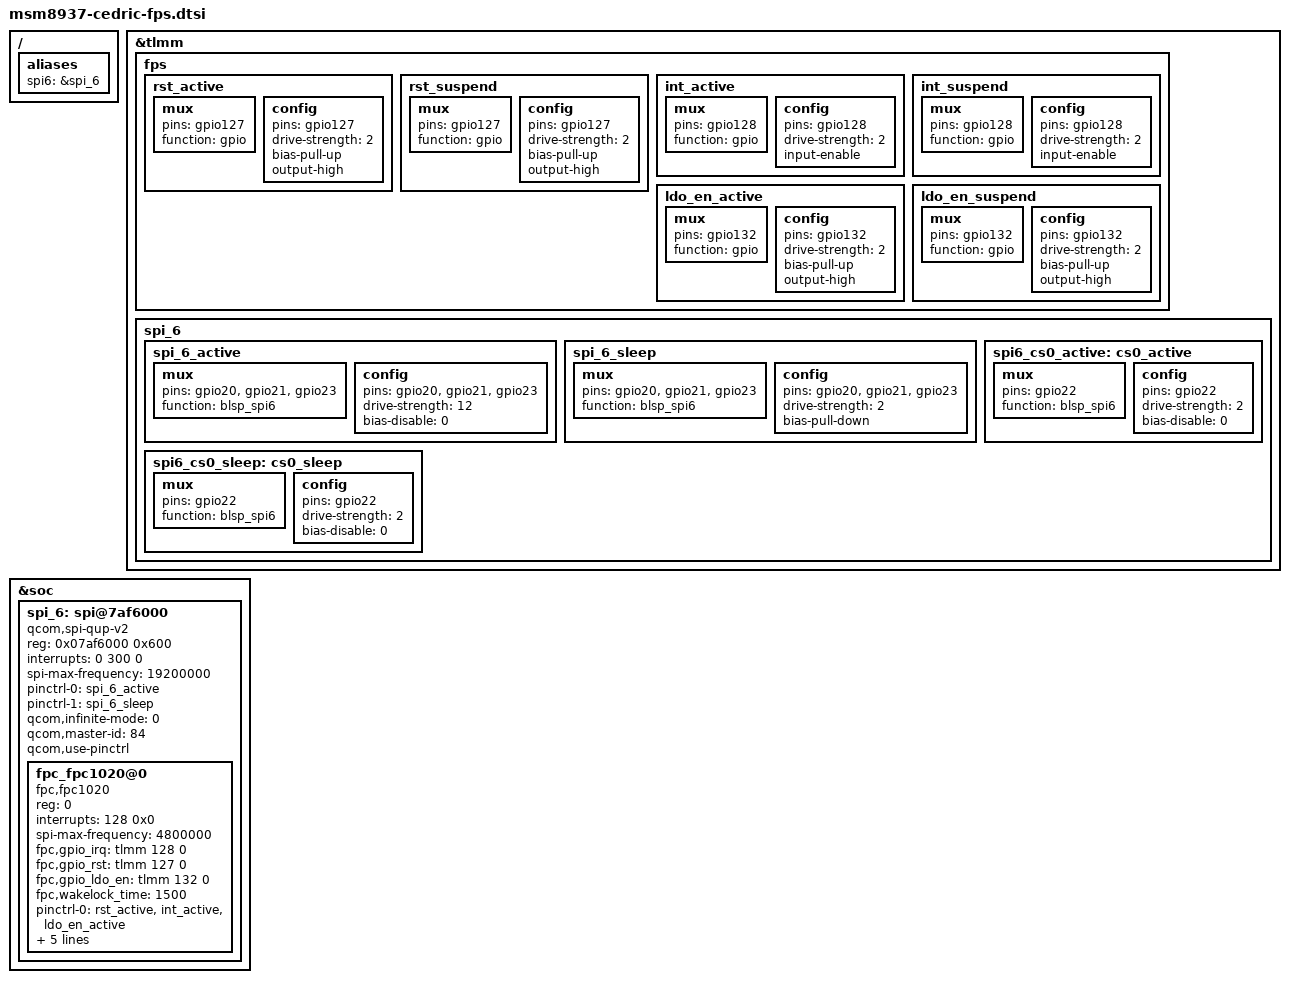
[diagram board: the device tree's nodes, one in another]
/* Copyright (c) 2016, Motorola Mobility Inc. All rights reserved.
 *
 * This program is free software; you can redistribute it and/or modify
 * it under the terms of the GNU General Public License version 2 and
 * only version 2 as published by the Free Software Foundation.
 *
 * This program is distributed in the hope that it will be useful,
 * but WITHOUT ANY WARRANTY; without even the implied warranty of
 * MERCHANTABILITY or FITNESS FOR A PARTICULAR PURPOSE.  See the
 * GNU General Public License for more details.
 */

/ {
	aliases {
		spi6 = &spi_6;
	};
};

&tlmm {
	fps: fps {
		rst_active: rst_active {
			/* RESET */
			mux {
				pins = "gpio127";
				function = "gpio";
			};

			config {
				pins = "gpio127";
				drive-strength = <2>; /* 2 MA */
				bias-pull-up; /* pull up */
				output-high;
			};
		};

		rst_suspend: rst_suspend{
			/* RESET */
			mux {
				pins = "gpio127";
				function = "gpio";
			};

			config {
				pins = "gpio127";
				drive-strength = <2>; /* 2 MA */
				bias-pull-up; /* pull up */
				output-high;
			};
		};

		int_active: int_active {
			/* INTERRUPT */
			mux {
				pins = "gpio128";
				function = "gpio";
			};

			config {
				pins = "gpio128";
				drive-strength = <2>; /* 2 MA */
				input-enable;
			};
		};

		int_suspend: int_suspend{
			/* INTERRUPT */
			mux {
				pins = "gpio128";
				function = "gpio";
			};

			config {
				pins = "gpio128";
				drive-strength = <2>; /* 2 MA */
				input-enable;
			};
		};

		ldo_en_active: ldo_en_active {
			/* LDO_EN */
			mux {
				pins = "gpio132";
				function = "gpio";
			};

			config {
				pins = "gpio132";
				drive-strength = <2>; /* 2 MA */
				bias-pull-up; /* pull up */
				output-high;
			};
		};

		ldo_en_suspend: ldo_en_suspend{
			/* LDO_EN */
			mux {
				pins = "gpio132";
				function = "gpio";
			};

			config {
				pins = "gpio132";
				drive-strength = <2>; /* 2 MA */
				bias-pull-up; /* pull up */
				output-high;
			};
		};
	};

	spi_6 {
		spi_6_active: spi_6_active {
			mux {
				/* MOSI, MISO, CLK */
				pins = "gpio20", "gpio21", "gpio23";
				function = "blsp_spi6";
			};

			config {
				pins = "gpio20", "gpio21", "gpio23";
				drive-strength = <12>; /* 12 MA */
				bias-disable = <0>; /* No PULL */
			};
		};

		spi_6_sleep: spi_6_sleep {
			mux {
				/* MOSI, MISO, CLK */
				pins = "gpio20", "gpio21", "gpio23";
				function = "blsp_spi6";
			};

			config {
				pins = "gpio20", "gpio21", "gpio23";
				drive-strength = <2>; /* 2 MA */
				bias-pull-down; /* PULL Down */
			};
		};

		spi6_cs0_active: cs0_active {
			mux {
				pins = "gpio22";
				function = "blsp_spi6";
			};

			config {
				pins = "gpio22";
				drive-strength = <2>;
				bias-disable = <0>;
			};
		};

		spi6_cs0_sleep: cs0_sleep {
			mux {
				pins = "gpio22";
				function = "blsp_spi6";
			};

			config {
				pins = "gpio22";
				drive-strength = <2>;
				bias-disable = <0>;
			};
		};
	};
};

&soc {
	spi_6: spi@7af6000 { /* BLSP2 QUP2 */
		compatible = "qcom,spi-qup-v2";
		status = "ok";
		#address-cells = <1>;
		#size-cells = <0>;
		reg-names = "spi_physical";
		reg = <0x07af6000 0x600>;
		interrupt-names = "spi_irq";
		interrupts = <0 300 0>;
		spi-max-frequency = <19200000>;

		pinctrl-names = "spi_default", "spi_sleep";
		pinctrl-0 = <&spi_6_active>;
		pinctrl-1 = <&spi_6_sleep>;
		qcom,infinite-mode = <0>;
		qcom,master-id = <84>;
		qcom,use-pinctrl;

		fpc_fpc1020@0{
			compatible = "fpc,fpc1020";
			status = "ok";
			reg = <0>;
			interrupts = <128 0x0>;
			spi-max-frequency = <4800000>;
			fpc,gpio_irq = <&tlmm 128 0>;
			fpc,gpio_rst = <&tlmm 127 0>;
			fpc,gpio_ldo_en = <&tlmm 132 0>;
			fpc,wakelock_time = <1500>;
			pinctrl-names = "default", "suspend";
			pinctrl-0 = <&rst_active &int_active &ldo_en_active>;
			pinctrl-1 = <&rst_suspend &int_suspend &ldo_en_suspend>;
			fpc,txout_boost_enable;
			clock-names = "iface_clk", "core_clk";
			clocks = <&clock_gcc clk_gcc_blsp2_ahb_clk>,
			<&clock_gcc clk_gcc_blsp2_qup2_spi_apps_clk>;
		};
	};
};

